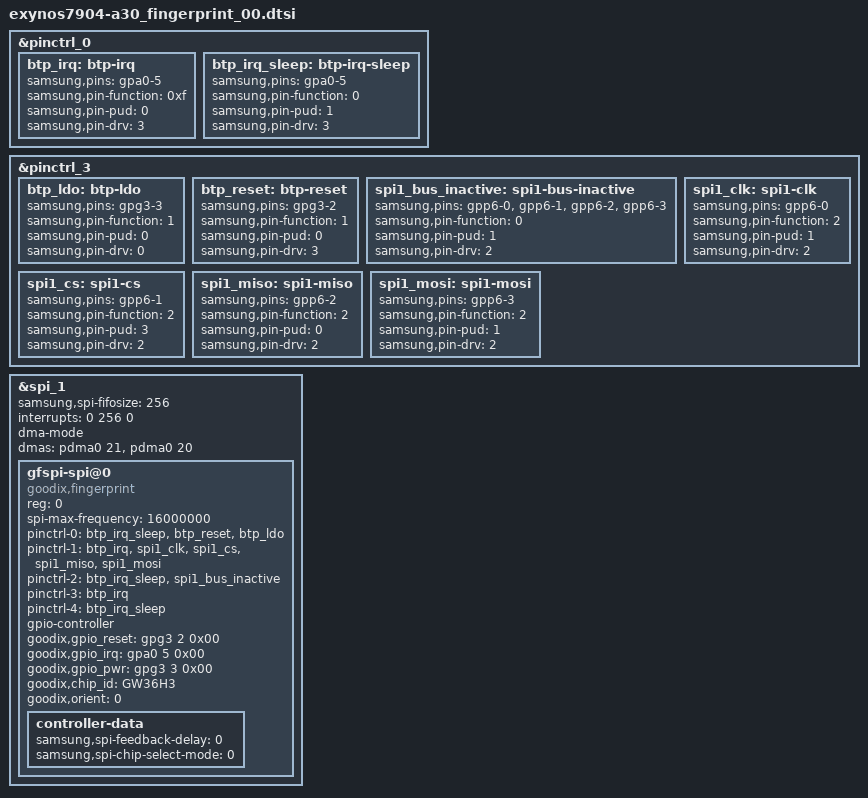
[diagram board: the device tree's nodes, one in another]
/*
 * Copyright (c) 2012-2013, The Linux Foundation. All rights reserved.
 *
 * This program is free software; you can redistribute it and/or modify
 * it under the terms of the GNU General Public License version 2 and
 * only version 2 as published by the Free Software Foundation.
 *
 * This program is distributed in the hope that it will be useful,
 * but WITHOUT ANY WARRANTY; without even the implied warranty of
 * MERCHANTABILITY or FITNESS FOR A PARTICULAR PURPOSE.  See the
 * GNU General Public License for more details.
 */

&pinctrl_0 {
	btp_irq: btp-irq {
		samsung,pins = "gpa0-5";
		samsung,pin-function = <0xf>;
		samsung,pin-pud = <0>;
		samsung,pin-drv = <3>;
	};

	btp_irq_sleep: btp-irq-sleep {
		samsung,pins = "gpa0-5";
		samsung,pin-function = <0>;
		samsung,pin-pud = <1>;
		samsung,pin-drv = <3>;
	};
};

&pinctrl_3 {
	btp_ldo: btp-ldo {
		samsung,pins = "gpg3-3";
		samsung,pin-function = <1>;
		samsung,pin-pud = <0>;
		samsung,pin-drv = <0>;
	};

	btp_reset: btp-reset {
		samsung,pins = "gpg3-2";
		samsung,pin-function = <1>;
		samsung,pin-pud = <0>;
		samsung,pin-drv = <3>;
	};

	/* SPI_FP */
	spi1_bus_inactive: spi1-bus-inactive {
		samsung,pins = "gpp6-0", "gpp6-1", "gpp6-2", "gpp6-3";
		samsung,pin-function = <0>;
		samsung,pin-pud = <1>;
		samsung,pin-drv = <2>;
	};

	spi1_clk: spi1-clk {
		samsung,pins = "gpp6-0";
		samsung,pin-function = <2>;
		samsung,pin-pud = <1>;
		samsung,pin-drv = <2>;
	};

	spi1_cs: spi1-cs {
		samsung,pins = "gpp6-1";
		samsung,pin-function = <2>;
		samsung,pin-pud = <3>;
		samsung,pin-drv = <2>;
	};

	spi1_miso: spi1-miso {
		samsung,pins = "gpp6-2";
		samsung,pin-function = <2>;
		samsung,pin-pud = <0>;
		samsung,pin-drv = <2>;
	};

	spi1_mosi: spi1-mosi {
		samsung,pins = "gpp6-3";
		samsung,pin-function = <2>;
		samsung,pin-pud = <1>;
		samsung,pin-drv = <2>;
	};
};

&spi_1 {
	status = "okay";
	#address-cells = <1>;
	#size-cells = <0>;
	/delete-property/ pinctrl-names;
	/delete-property/ pinctrl-0;
	samsung,spi-fifosize = <256>;
	interrupts = <0 256 0>;

	dma-mode;
	dmas = <&pdma0 21
		&pdma0 20>;

	gfspi-spi@0 {
		compatible = "goodix,fingerprint";
		reg = <0>;
		spi-max-frequency = <16000000>;
		pinctrl-names = "default", "pins_poweron", "pins_poweroff"
						, "pins_poweron_tz", "pins_poweroff_tz";
		pinctrl-0 = <&btp_irq_sleep &btp_reset &btp_ldo>;
		pinctrl-1 = <&btp_irq &spi1_clk &spi1_cs &spi1_miso &spi1_mosi>;
		pinctrl-2 = <&btp_irq_sleep &spi1_bus_inactive>;
		pinctrl-3 = <&btp_irq>;
		pinctrl-4 = <&btp_irq_sleep>;

		gpio-controller;
		#gpio-cells = <2>;

		goodix,gpio_reset = <&gpg3 2 0x00>;
		goodix,gpio_irq = <&gpa0 5 0x00>;
		goodix,gpio_pwr = <&gpg3 3 0x00>;
		goodix,chip_id = "GW36H3";
		goodix,orient = <0>;

		controller-data {
			samsung,spi-feedback-delay = <0>;
			samsung,spi-chip-select-mode = <0>;
		};
	};
};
